# PIC32MZ2048EFM144 register map
Registers are 32-bit, access not given, reset 0x0 unless marked. A register's access mark holds for its fields unless they carry their own. Offsets are from the block's base; [hi:lo] are bit positions; {n}, {i} and the like mark numbered series; 'fields as' and 'values as' point back to an identical list.

## CMP2 — CMP2 peripheral
Base 0xBF84C010
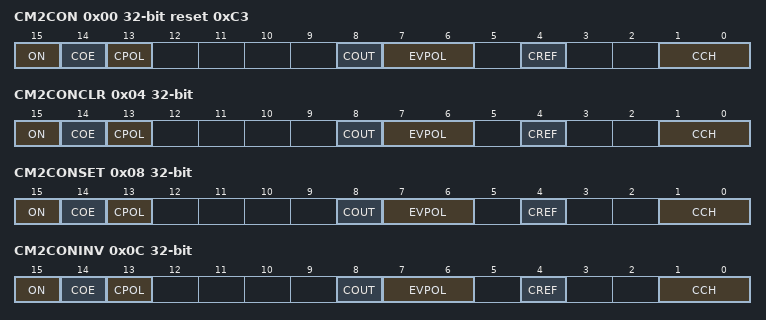
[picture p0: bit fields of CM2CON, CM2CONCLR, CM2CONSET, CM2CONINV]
0x00 CM2CON reset 0xC3
  [15] ON, [14] COE, [13] CPOL, [8] COUT, [7:6] EVPOL, [4] CREF, [1:0] CCH
0x04 CM2CONCLR
  fields as CM2CON
0x08 CM2CONSET
  fields as CM2CON
0x0C CM2CONINV
  fields as CM2CON

## CMP — CMP peripheral
Base 0xBF84C060
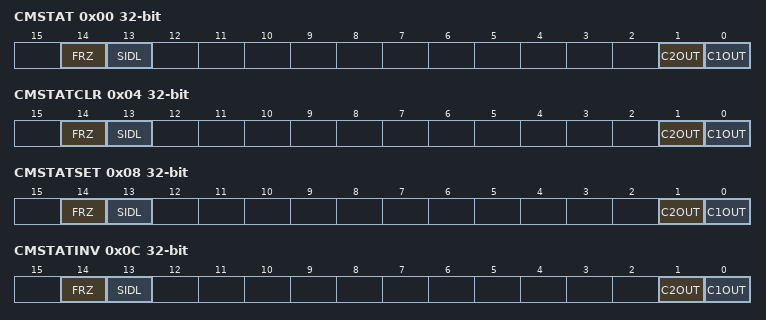
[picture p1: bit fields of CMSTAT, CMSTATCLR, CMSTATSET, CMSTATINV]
0x00 CMSTAT
  [14] FRZ, [13] SIDL, [1] C2OUT, [0] C1OUT
0x04 CMSTATCLR
  [14] FRZ, [13] SIDL, [1] C2OUT, [0] C1OUT
0x08 CMSTATSET
  [14] FRZ, [13] SIDL, [1] C2OUT, [0] C1OUT
0x0C CMSTATINV
  [14] FRZ, [13] SIDL, [1] C2OUT, [0] C1OUT

## PORTA — PORTA peripheral
Base 0xBF860000
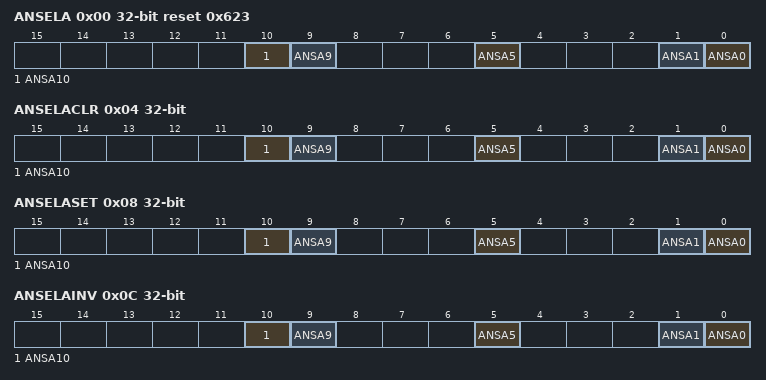
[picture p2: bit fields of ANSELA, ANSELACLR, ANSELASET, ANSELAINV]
0x00 ANSELA reset 0x623
  [10] ANSA10, [9] ANSA9, [5] ANSA5, [1] ANSA1, [0] ANSA0
0x04 ANSELACLR
  [10] ANSA10, [9] ANSA9, [5] ANSA5, [1] ANSA1, [0] ANSA0
0x08 ANSELASET
  [10] ANSA10, [9] ANSA9, [5] ANSA5, [1] ANSA1, [0] ANSA0
0x0C ANSELAINV
  [10] ANSA10, [9] ANSA9, [5] ANSA5, [1] ANSA1, [0] ANSA0
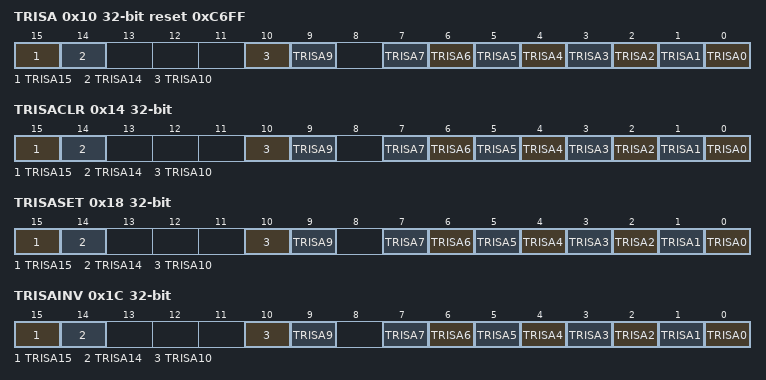
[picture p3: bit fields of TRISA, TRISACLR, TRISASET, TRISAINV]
0x10 TRISA reset 0xC6FF
  [15] TRISA15, [14] TRISA14, [10] TRISA10, [9] TRISA9, [n] TRISA{n} (n=0..7)
0x14 TRISACLR
  fields as TRISA
0x18 TRISASET
  fields as TRISA
0x1C TRISAINV
  fields as TRISA
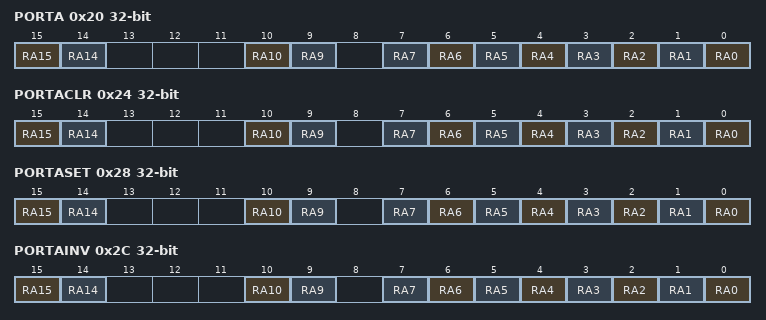
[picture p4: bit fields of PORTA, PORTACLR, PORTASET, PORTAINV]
0x20 PORTA
  [15] RA15, [14] RA14, [10] RA10, [9] RA9, [n] RA{n} (n=0..7)
0x24 PORTACLR
  [15] RA15, [14] RA14, [10] RA10, [9] RA9, [n] RA{n} (n=0..7)
0x28 PORTASET
  [15] RA15, [14] RA14, [10] RA10, [9] RA9, [n] RA{n} (n=0..7)
0x2C PORTAINV
  [15] RA15, [14] RA14, [10] RA10, [9] RA9, [n] RA{n} (n=0..7)
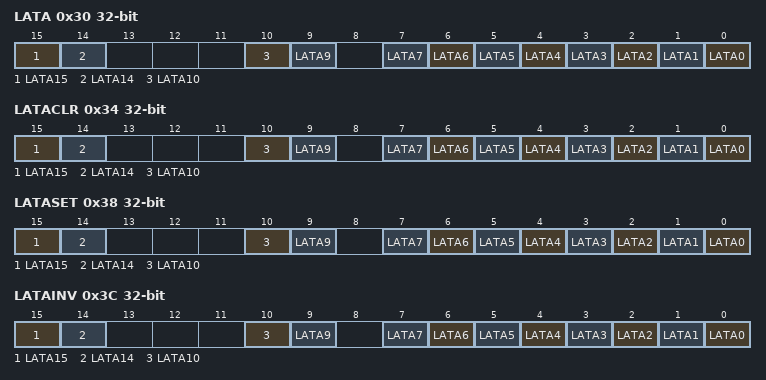
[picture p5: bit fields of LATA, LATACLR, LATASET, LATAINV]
0x30 LATA
  [15] LATA15, [14] LATA14, [10] LATA10, [9] LATA9, [n] LATA{n} (n=0..7)
0x34 LATACLR
  fields as LATA
0x38 LATASET
  fields as LATA
0x3C LATAINV
  fields as LATA
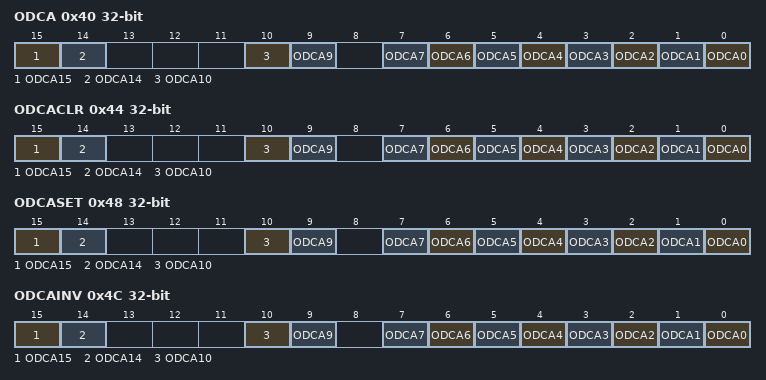
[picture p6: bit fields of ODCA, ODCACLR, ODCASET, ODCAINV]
0x40 ODCA
  [15] ODCA15, [14] ODCA14, [10] ODCA10, [9] ODCA9, [n] ODCA{n} (n=0..7)
0x44 ODCACLR
  fields as ODCA
0x48 ODCASET
  fields as ODCA
0x4C ODCAINV
  fields as ODCA
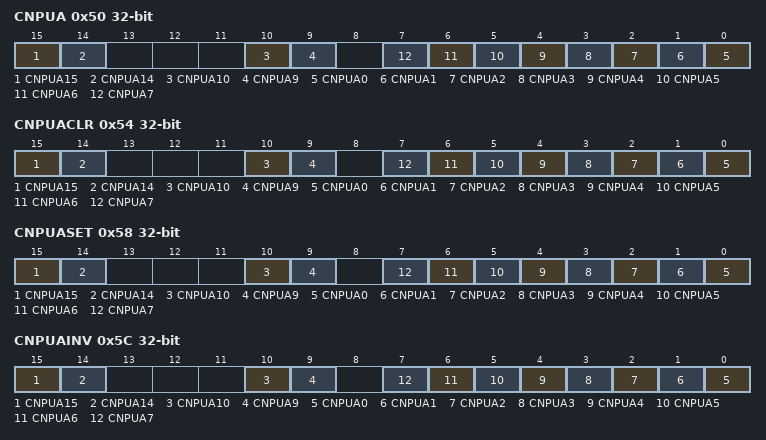
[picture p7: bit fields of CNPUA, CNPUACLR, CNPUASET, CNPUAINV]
0x50 CNPUA
  [15] CNPUA15, [14] CNPUA14, [10] CNPUA10, [9] CNPUA9, [n] CNPUA{n} (n=0..7)
0x54 CNPUACLR
  fields as CNPUA
0x58 CNPUASET
  fields as CNPUA
0x5C CNPUAINV
  fields as CNPUA
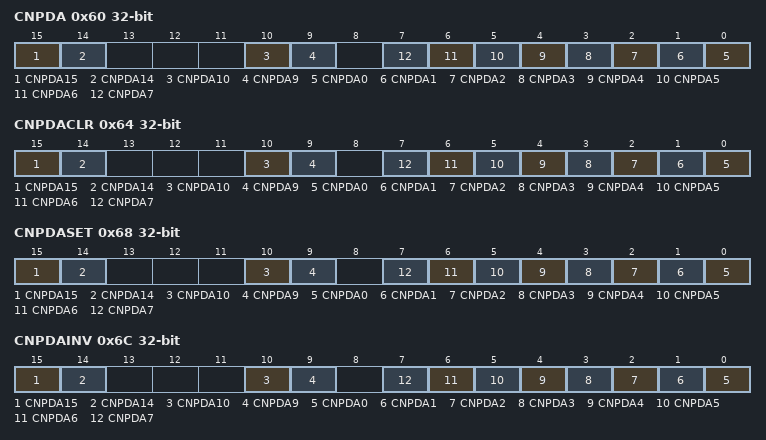
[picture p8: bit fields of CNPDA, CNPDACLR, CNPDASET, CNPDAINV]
0x60 CNPDA
  [15] CNPDA15, [14] CNPDA14, [10] CNPDA10, [9] CNPDA9, [n] CNPDA{n} (n=0..7)
0x64 CNPDACLR
  fields as CNPDA
0x68 CNPDASET
  fields as CNPDA
0x6C CNPDAINV
  fields as CNPDA
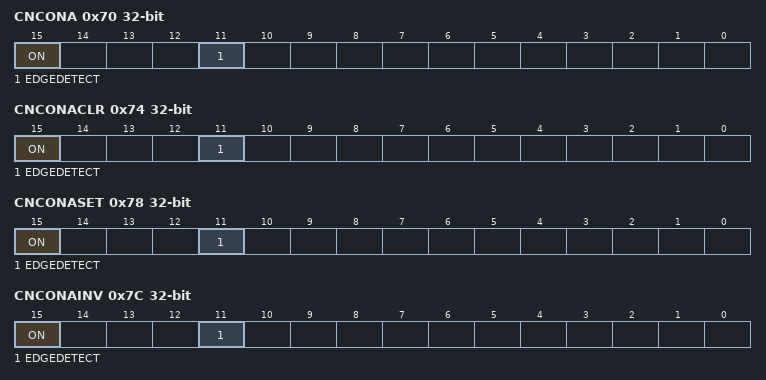
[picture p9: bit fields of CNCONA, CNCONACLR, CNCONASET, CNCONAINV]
0x70 CNCONA
  [15] ON, [11] EDGEDETECT
0x74 CNCONACLR
  [15] ON, [11] EDGEDETECT
0x78 CNCONASET
  [15] ON, [11] EDGEDETECT
0x7C CNCONAINV
  [15] ON, [11] EDGEDETECT
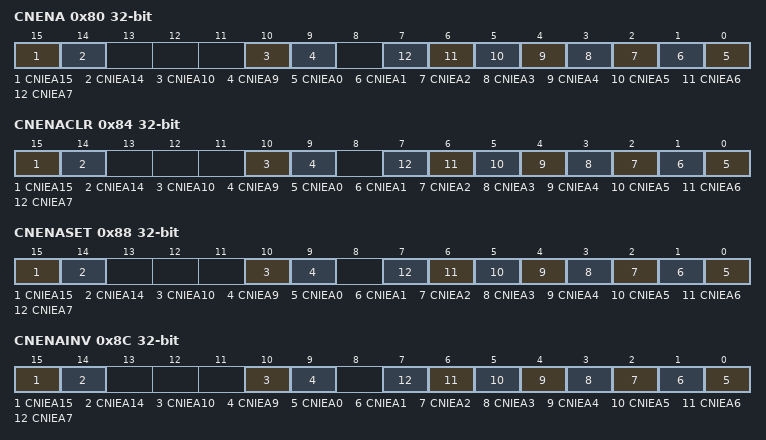
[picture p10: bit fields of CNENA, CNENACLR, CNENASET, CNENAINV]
0x80 CNENA
  [15] CNIEA15, [14] CNIEA14, [10] CNIEA10, [9] CNIEA9, [n] CNIEA{n} (n=0..7)
0x84 CNENACLR
  fields as CNENA
0x88 CNENASET
  fields as CNENA
0x8C CNENAINV
  fields as CNENA
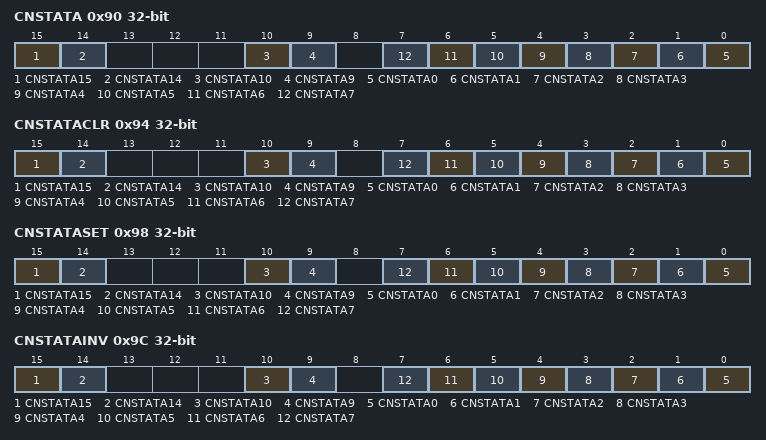
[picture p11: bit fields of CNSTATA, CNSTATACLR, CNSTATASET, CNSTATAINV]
0x90 CNSTATA
  [15] CNSTATA15, [14] CNSTATA14, [10] CNSTATA10, [9] CNSTATA9, [n] CNSTATA{n} (n=0..7)
0x94 CNSTATACLR
  fields as CNSTATA
0x98 CNSTATASET
  fields as CNSTATA
0x9C CNSTATAINV
  fields as CNSTATA
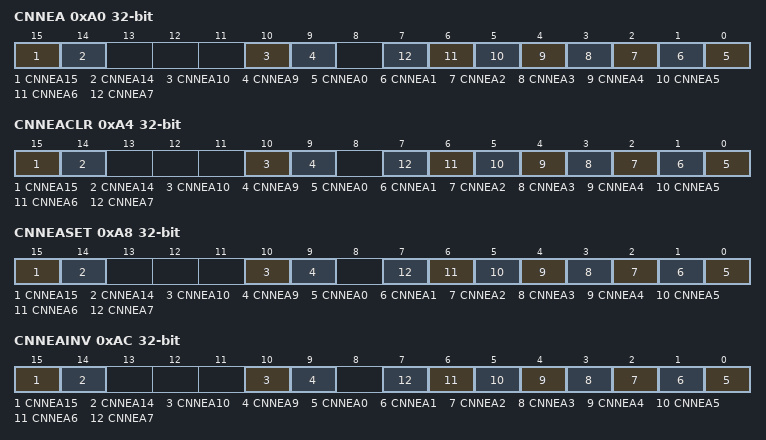
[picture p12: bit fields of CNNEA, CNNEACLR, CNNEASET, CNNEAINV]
0xA0 CNNEA
  [15] CNNEA15, [14] CNNEA14, [10] CNNEA10, [9] CNNEA9, [n] CNNEA{n} (n=0..7)
0xA4 CNNEACLR
  fields as CNNEA
0xA8 CNNEASET
  fields as CNNEA
0xAC CNNEAINV
  fields as CNNEA
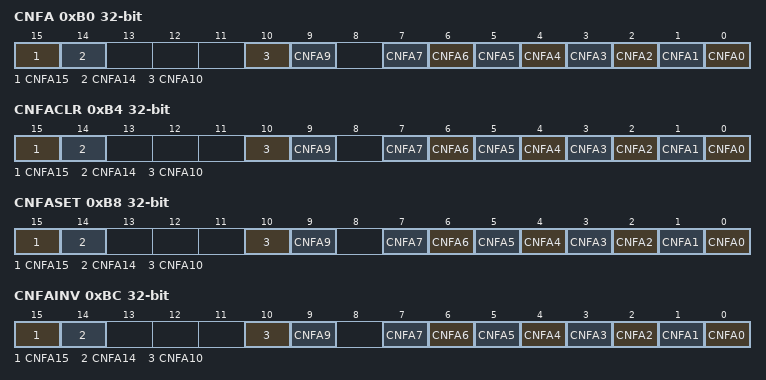
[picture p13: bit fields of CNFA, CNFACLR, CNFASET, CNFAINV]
0xB0 CNFA
  [15] CNFA15, [14] CNFA14, [10] CNFA10, [9] CNFA9, [n] CNFA{n} (n=0..7)
0xB4 CNFACLR
  fields as CNFA
0xB8 CNFASET
  fields as CNFA
0xBC CNFAINV
  fields as CNFA
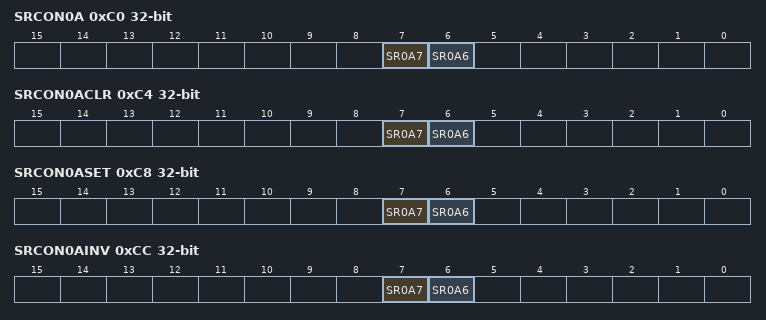
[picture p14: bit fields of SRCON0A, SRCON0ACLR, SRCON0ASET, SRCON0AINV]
0xC0 SRCON0A
  [7] SR0A7, [6] SR0A6
0xC4 SRCON0ACLR
  [7] SR0A7, [6] SR0A6
0xC8 SRCON0ASET
  [7] SR0A7, [6] SR0A6
0xCC SRCON0AINV
  [7] SR0A7, [6] SR0A6
0xD0 SRCON1A
  [7] SR1A7, [6] SR1A6
0xD4 SRCON1ACLR
  [7] SR1A7, [6] SR1A6
0xD8 SRCON1ASET
  [7] SR1A7, [6] SR1A6
0xDC SRCON1AINV
  [7] SR1A7, [6] SR1A6

## PORTB — PORTB peripheral
Base 0xBF860100
0x00 ANSELB reset 0xFFFF
  [n] ANSB{n} (n=0..15)
0x04 ANSELBCLR
  [n] ANSB{n} (n=0..15)
0x08 ANSELBSET
  [n] ANSB{n} (n=0..15)
0x0C ANSELBINV
  [n] ANSB{n} (n=0..15)
0x10 TRISB reset 0xFFFF
  [n] TRISB{n} (n=0..15)
0x14 TRISBCLR
  [n] TRISB{n} (n=0..15)
0x18 TRISBSET
  [n] TRISB{n} (n=0..15)
0x1C TRISBINV
  [n] TRISB{n} (n=0..15)
0x20 PORTB
  [n] RB{n} (n=0..15)
0x24 PORTBCLR
  [n] RB{n} (n=0..15)
0x28 PORTBSET
  [n] RB{n} (n=0..15)
0x2C PORTBINV
  [n] RB{n} (n=0..15)
0x30 LATB
  [n] LATB{n} (n=0..15)
0x34 LATBCLR
  [n] LATB{n} (n=0..15)
0x38 LATBSET
  [n] LATB{n} (n=0..15)
0x3C LATBINV
  [n] LATB{n} (n=0..15)
0x40 ODCB
  [n] ODCB{n} (n=0..15)
0x44 ODCBCLR
  [n] ODCB{n} (n=0..15)
0x48 ODCBSET
  [n] ODCB{n} (n=0..15)
0x4C ODCBINV
  [n] ODCB{n} (n=0..15)
0x50 CNPUB
  [n] CNPUB{n} (n=0..15)
0x54 CNPUBCLR
  [n] CNPUB{n} (n=0..15)
0x58 CNPUBSET
  [n] CNPUB{n} (n=0..15)
0x5C CNPUBINV
  [n] CNPUB{n} (n=0..15)
0x60 CNPDB
  [n] CNPDB{n} (n=0..15)
0x64 CNPDBCLR
  [n] CNPDB{n} (n=0..15)
0x68 CNPDBSET
  [n] CNPDB{n} (n=0..15)
0x6C CNPDBINV
  [n] CNPDB{n} (n=0..15)
0x70 CNCONB
  [15] ON, [11] EDGEDETECT
0x74 CNCONBCLR
  [15] ON, [11] EDGEDETECT
0x78 CNCONBSET
  [15] ON, [11] EDGEDETECT
0x7C CNCONBINV
  [15] ON, [11] EDGEDETECT
0x80 CNENB
  [n] CNIEB{n} (n=0..15)
0x84 CNENBCLR
  [n] CNIEB{n} (n=0..15)
0x88 CNENBSET
  [n] CNIEB{n} (n=0..15)
0x8C CNENBINV
  [n] CNIEB{n} (n=0..15)
0x90 CNSTATB
  [n] CNSTATB{n} (n=0..15)
0x94 CNSTATBCLR
  [n] CNSTATB{n} (n=0..15)
0x98 CNSTATBSET
  [n] CNSTATB{n} (n=0..15)
0x9C CNSTATBINV
  [n] CNSTATB{n} (n=0..15)
0xA0 CNNEB
  [n] CNNEB{n} (n=0..15)
0xA4 CNNEBCLR
  [n] CNNEB{n} (n=0..15)
0xA8 CNNEBSET
  [n] CNNEB{n} (n=0..15)
0xAC CNNEBINV
  [n] CNNEB{n} (n=0..15)
0xB0 CNFB
  [n] CNFB{n} (n=0..15)
0xB4 CNFBCLR
  [n] CNFB{n} (n=0..15)
0xB8 CNFBSET
  [n] CNFB{n} (n=0..15)
0xBC CNFBINV
  [n] CNFB{n} (n=0..15)
0xC0 SRCON0B
  [14] SR0B14, [10] SR0B10, [9] SR0B9, [8] SR0B8, [5] SR0B5, [3] SR0B3
0xC4 SRCON0BCLR
  [14] SR0B14, [10] SR0B10, [9] SR0B9, [8] SR0B8, [5] SR0B5, [3] SR0B3
0xC8 SRCON0BSET
  [14] SR0B14, [10] SR0B10, [9] SR0B9, [8] SR0B8, [5] SR0B5, [3] SR0B3
0xCC SRCON0BINV
  [14] SR0B14, [10] SR0B10, [9] SR0B9, [8] SR0B8, [5] SR0B5, [3] SR0B3
0xD0 SRCON1B
  [14] SR1B14, [10] SR1B10, [9] SR1B9, [8] SR1B8, [5] SR1B5, [3] SR1B3
0xD4 SRCON1BCLR
  [14] SR1B14, [10] SR1B10, [9] SR1B9, [8] SR1B8, [5] SR1B5, [3] SR1B3
0xD8 SRCON1BSET
  [14] SR1B14, [10] SR1B10, [9] SR1B9, [8] SR1B8, [5] SR1B5, [3] SR1B3
0xDC SRCON1BINV
  [14] SR1B14, [10] SR1B10, [9] SR1B9, [8] SR1B8, [5] SR1B5, [3] SR1B3
